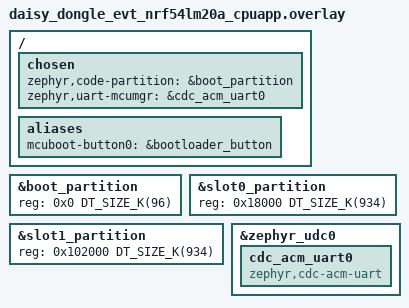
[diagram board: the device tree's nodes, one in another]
/*
 * Copyright (c) 2026 Framework Computer Inc
 *
 * SPDX-License-Identifier: Apache-2.0
 */

/ {
	chosen {
		/* MCUboot must be placed in the boot partition, not slot0 */
		zephyr,code-partition = &boot_partition;
		/*
		 * Redirect uart-mcumgr away from the console UART (uart20)
		 * to satisfy the compile-time check in serial_adapter.c.
		 * The CDC ACM code path does not read this chosen — it
		 * discovers the cdc_acm_uart device directly.
		 */
		zephyr,uart-mcumgr = &cdc_acm_uart0;
	};

	aliases {
		mcuboot-button0 = &bootloader_button;
	};
};

/* Enlarge boot partition to 96 KB for the new USB stack, shift slot0 */
&boot_partition {
	reg = <0x0 DT_SIZE_K(96)>;
};

&slot0_partition {
	reg = <0x18000 DT_SIZE_K(934)>;
};

&slot1_partition {
	reg = <0x102000 DT_SIZE_K(934)>;
};

/* Add USB CDC ACM device for MCUboot serial recovery */
&zephyr_udc0 {
	cdc_acm_uart0: cdc_acm_uart0 {
		compatible = "zephyr,cdc-acm-uart";
	};
};
